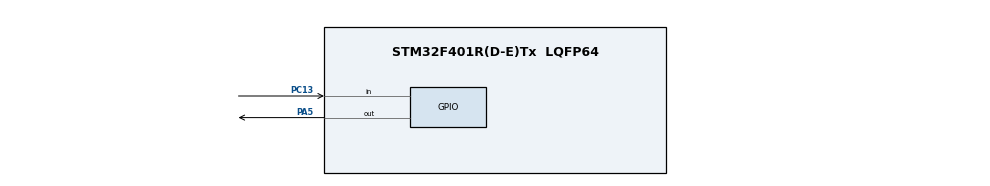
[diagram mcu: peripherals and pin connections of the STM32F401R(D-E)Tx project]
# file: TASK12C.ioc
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Mcu.Family=STM32F4
Mcu.Name=STM32F401R(D-E)Tx
Mcu.Package=LQFP64
PA5.Signal=GPIO_Output
PA5.GPIO_Speed=GPIO_SPEED_FREQ_LOW
PA5.GPIO_Output_Level=GPIO_PIN_RESET
PA13.Mode=Serial_Wire
PA13.Signal=SYS_JTMS-SWDIO
PA14.Mode=Serial_Wire
PA14.Signal=SYS_JTCK-SWCLK
PC13.Signal=GPIO_Input
PC13.GPIO_PuPd=GPIO_NOPULL
ProjectManager.TargetToolchain=MDK-ARM V5.32
RCC.AHBFreq_Value=84000000
RCC.APB1Freq_Value=42000000
RCC.APB2Freq_Value=84000000
RCC.CortexFreq_Value=84000000
RCC.HCLKFreq_Value=84000000
RCC.SYSCLKFreq_VALUE=84000000
RCC.SYSCLKSource=RCC_SYSCLKSOURCE_PLLCLK
board=custom

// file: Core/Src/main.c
/* USER CODE BEGIN Header */
/**
  ******************************************************************************
  * @file           : main.c
  * @brief          : CAT 11 - TASK 11B: PC13 Button State Remembrance
  * Target Device   : STM32F401RET6 (NUCLEO-F401RE, ARM Cortex-M4 @ 84 MHz)
  * Pin Map         : PA5  -> Onboard Green LED LD2 (Active-HIGH)
  *                   PC13 -> User Push-Button B1 (Active-LOW with Internal Pull-up)
  ******************************************************************************
  */
/* USER CODE END Header */
#include "main.h"

/* USER CODE BEGIN Includes */
#include <stdbool.h>
/* USER CODE END Includes */

/* USER CODE BEGIN PV */
uint8_t last_btn_val = GPIO_PIN_SET;
uint32_t last_btn_tick = 0;
/* USER CODE END PV */

void SystemClock_Config(void);
static void MX_GPIO_Init(void);

int main(void)
{

  /* MCU Configuration--------------------------------------------------------*/

  /* Reset of all peripherals, Initializes the Flash interface and the Systick. */
  HAL_Init();

  /* Configure the system clock */
  SystemClock_Config();

  /* Initialize all configured peripherals */
  MX_GPIO_Init();
  /* USER CODE BEGIN 2 */
  /* Ensure LD2 is initially OFF */
  HAL_GPIO_WritePin(GPIOA, GPIO_PIN_5, GPIO_PIN_RESET);
  /* USER CODE END 2 */

  /* Infinite loop */
  /* USER CODE BEGIN WHILE */
  while (1)
  {
        if (HAL_GPIO_ReadPin(GPIOC, GPIO_PIN_13) == GPIO_PIN_SET)
    {
      HAL_Delay(25);
      if (HAL_GPIO_ReadPin(GPIOC, GPIO_PIN_13) == GPIO_PIN_SET)
      {
        uint32_t press_start = HAL_GetTick();
        while (HAL_GPIO_ReadPin(GPIOC, GPIO_PIN_13) == GPIO_PIN_SET);
        uint32_t duration = HAL_GetTick() - press_start;
        if (duration < 1000)
        {
          /* Short press (< 1s): Toggle LED */
          HAL_GPIO_TogglePin(GPIOA, GPIO_PIN_5);
        }
        else
        {
          /* Long press (>= 1s): 5 rapid alert blinks */
          for (int k = 0; k < 10; k++)
          {
            HAL_GPIO_TogglePin(GPIOA, GPIO_PIN_5);
            HAL_Delay(80);
          }
        }
      }
    }
  /* USER CODE END 3 */
}
}

void SystemClock_Config(void)
{
  RCC_OscInitTypeDef RCC_OscInitStruct = {0};
  RCC_ClkInitTypeDef RCC_ClkInitStruct = {0};

  __HAL_RCC_PWR_CLK_ENABLE();
  __HAL_PWR_VOLTAGESCALING_CONFIG(PWR_REGULATOR_VOLTAGE_SCALE2);

  RCC_OscInitStruct.OscillatorType = RCC_OSCILLATORTYPE_HSI;
  RCC_OscInitStruct.HSIState = RCC_HSI_ON;
  RCC_OscInitStruct.HSICalibrationValue = RCC_HSICALIBRATION_DEFAULT;
  RCC_OscInitStruct.PLL.PLLState = RCC_PLL_ON;
  RCC_OscInitStruct.PLL.PLLSource = RCC_PLLSOURCE_HSI;
  RCC_OscInitStruct.PLL.PLLM = 16;
  RCC_OscInitStruct.PLL.PLLN = 336;
  RCC_OscInitStruct.PLL.PLLP = RCC_PLLP_DIV4;
  RCC_OscInitStruct.PLL.PLLQ = 7;
  if (HAL_RCC_OscConfig(&RCC_OscInitStruct) != HAL_OK)
  {
    Error_Handler();
  }

  RCC_ClkInitStruct.ClockType = RCC_CLOCKTYPE_HCLK|RCC_CLOCKTYPE_SYSCLK
                              |RCC_CLOCKTYPE_PCLK1|RCC_CLOCKTYPE_PCLK2;
  RCC_ClkInitStruct.SYSCLKSource = RCC_SYSCLKSOURCE_PLLCLK;
  RCC_ClkInitStruct.AHBCLKDivider = RCC_SYSCLK_DIV1;
  RCC_ClkInitStruct.APB1CLKDivider = RCC_HCLK_DIV2;
  RCC_ClkInitStruct.APB2CLKDivider = RCC_HCLK_DIV1;

  if (HAL_RCC_ClockConfig(&RCC_ClkInitStruct, FLASH_LATENCY_2) != HAL_OK)
  {
    Error_Handler();
  }
}

static void MX_GPIO_Init(void)
{
  GPIO_InitTypeDef GPIO_InitStruct = {0};

  /* GPIO Ports Clock Enable */
  __HAL_RCC_GPIOC_CLK_ENABLE();
  __HAL_RCC_GPIOH_CLK_ENABLE();
  __HAL_RCC_GPIOA_CLK_ENABLE();

  /* Configure GPIO pin Output Level */
  HAL_GPIO_WritePin(GPIOA, GPIO_PIN_5, GPIO_PIN_RESET);

  /* Configure GPIO pin : PC13 (User Button B1 with Pull-up) */
  GPIO_InitStruct.Pin = GPIO_PIN_13;
  GPIO_InitStruct.Mode = GPIO_MODE_INPUT;
  GPIO_InitStruct.Pull = GPIO_NOPULL;
  HAL_GPIO_Init(GPIOC, &GPIO_InitStruct);

  /* Configure GPIO pin : PA5 (User LED LD2) */
  GPIO_InitStruct.Pin = GPIO_PIN_5;
  GPIO_InitStruct.Mode = GPIO_MODE_OUTPUT_PP;
  GPIO_InitStruct.Pull = GPIO_NOPULL;
  GPIO_InitStruct.Speed = GPIO_SPEED_FREQ_LOW;
  HAL_GPIO_Init(GPIOA, &GPIO_InitStruct);
}

void Error_Handler(void)
{
  __disable_irq();
  while (1)
  {
  }
}
